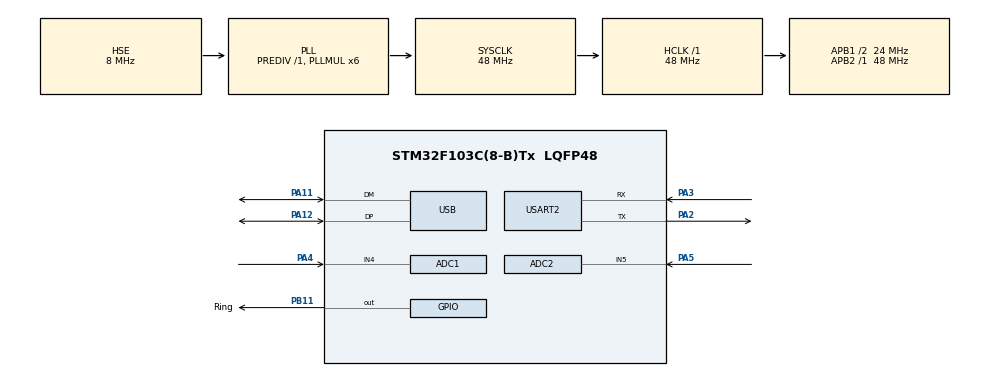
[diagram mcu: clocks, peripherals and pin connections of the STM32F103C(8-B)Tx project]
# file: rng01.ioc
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ADC1.Channel-0\#ChannelRegularConversion=ADC_CHANNEL_4
ADC1.NbrOfConversionFlag=1
ADC1.Rank-0\#ChannelRegularConversion=1
ADC1.SamplingTime-0\#ChannelRegularConversion=ADC_SAMPLETIME_1CYCLE_5
ADC1.master=1
ADC2.Channel-0\#ChannelRegularConversion=ADC_CHANNEL_5
ADC2.NbrOfConversionFlag=1
ADC2.Rank-0\#ChannelRegularConversion=1
ADC2.SamplingTime-0\#ChannelRegularConversion=ADC_SAMPLETIME_1CYCLE_5
FREERTOS.Tasks01=defaultTask,24,128,StartDefaultTask,Default,NULL,Dynamic,NULL,NULL
Mcu.Family=STM32F1
Mcu.Name=STM32F103C(8-B)Tx
Mcu.Package=LQFP48
NVIC.ADC1_2_IRQn=true\:5\:0\:false\:false\:true\:true\:true\:true\:true
NVIC.PriorityGroup=NVIC_PRIORITYGROUP_4
NVIC.RTC_Alarm_IRQn=true\:5\:0\:false\:false\:true\:true\:true\:true\:true
NVIC.RTC_IRQn=true\:5\:0\:false\:false\:true\:true\:true\:true\:true
NVIC.USBWakeUp_IRQn=true\:5\:0\:false\:false\:true\:true\:false\:true\:true
NVIC.USB_LP_CAN1_RX0_IRQn=true\:5\:0\:false\:false\:true\:true\:false\:true\:true
PA11.Mode=Device
PA11.Signal=USB_DM
PA12.Mode=Device
PA12.Signal=USB_DP
PA13.Mode=Serial_Wire
PA13.Signal=SYS_JTMS-SWDIO
PA14.Mode=Serial_Wire
PA14.Signal=SYS_JTCK-SWCLK
PA2.Mode=Asynchronous
PA2.Signal=USART2_TX
PA3.Mode=Asynchronous
PA3.Signal=USART2_RX
PA4.Signal=ADCx_IN4
PA5.Signal=ADCx_IN5
PB11.GPIO_Label=Ring
PB11.GPIO_Speed=GPIO_SPEED_FREQ_HIGH
PB11.PinState=GPIO_PIN_SET
PB11.Signal=GPIO_Output
PD0-OSC_IN.Mode=HSE-External-Oscillator
PD0-OSC_IN.Signal=RCC_OSC_IN
PD1-OSC_OUT.Mode=HSE-External-Oscillator
PD1-OSC_OUT.Signal=RCC_OSC_OUT
ProjectManager.HeapSize=0x200
ProjectManager.StackSize=0x400
ProjectManager.TargetToolchain=Makefile
RCC.ADCPresc=RCC_ADCPCLK2_DIV6
RCC.AHBFreq_Value=48000000
RCC.APB1CLKDivider=RCC_HCLK_DIV2
RCC.APB1Freq_Value=24000000
RCC.APB1TimFreq_Value=48000000
RCC.APB2Freq_Value=48000000
RCC.APB2TimFreq_Value=48000000
RCC.HCLKFreq_Value=48000000
RCC.PLLMUL=RCC_PLL_MUL6
RCC.SYSCLKFreq_VALUE=48000000
RCC.SYSCLKSource=RCC_SYSCLKSOURCE_PLLCLK
RCC.USBFreq_Value=48000000
SH.ADCx_IN4.0=ADC1_IN4,IN4
SH.ADCx_IN5.0=ADC2_IN5,IN5
TIM1.Period=0xffff-1
TIM1.Prescaler=48 -1
TIM1.RepetitionCounter=0
USART2.VirtualMode=VM_ASYNC
USB.low_power_enable=ENABLE
USB.lpm_enable=ENABLE
USB_DEVICE.CLASS_NAME_FS=CDC
USB_DEVICE.MANUFACTURER_STRING=EOS
USB_DEVICE.PRODUCT_STRING_CDC_FS=BluePill
USB_DEVICE.VirtualMode=Cdc
USB_DEVICE.VirtualModeFS=Cdc_FS
VP_FREERTOS_VS_CMSIS_V2.Mode=CMSIS_V2
VP_RTC_VS_RTC_Activate.Mode=RTC_Enabled
VP_TIM1_VS_ClockSourceINT.Mode=Internal
VP_USB_DEVICE_VS_USB_DEVICE_CDC_FS.Mode=CDC_FS
board=custom

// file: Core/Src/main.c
/* USER CODE BEGIN Header */
/**
  ******************************************************************************
  * @file           : main.c
  * @brief          : Main program body
  ******************************************************************************
  * @attention
  *
  * Copyright (c) 2024 STMicroelectronics.
  * All rights reserved.
  *
  * This software is licensed under terms that can be found in the LICENSE file
  * in the root directory of this software component.
  * If no LICENSE file comes with this software, it is provided AS-IS.
  *
  ******************************************************************************
  */
/* USER CODE END Header */
#include "main.h"
#include "cmsis_os.h"
#include "usb_device.h"
#include "usbd_cdc_if.h"
#include "ring.h"

ADC_HandleTypeDef hadc1;
ADC_HandleTypeDef hadc2;

RTC_HandleTypeDef hrtc;

TIM_HandleTypeDef htim1;

UART_HandleTypeDef huart2;

/* Definitions for defaultTask */
osThreadId_t defaultTaskHandle;
const osThreadAttr_t defaultTask_attributes = {
  .name = "defaultTask",
  .stack_size = 128 * 4,
  .priority = (osPriority_t) osPriorityNormal,
};

void SystemClock_Config(void);
static void MX_GPIO_Init(void);
static void MX_USART2_UART_Init(void);
static void MX_ADC1_Init(void);
static void MX_ADC2_Init(void);
static void MX_RTC_Init(void);
static void MX_TIM1_Init(void);
void StartDefaultTask(void *argument);

/* USER CODE BEGIN 0 */

int _write(int file, char *ptr, int len) {
    CDC_Transmit_FS((uint8_t*) ptr, len); return len;
}

/* USER CODE END 0 */

int main(void)
{

  /* MCU Configuration--------------------------------------------------------*/

  /* Reset of all peripherals, Initializes the Flash interface and the Systick. */
  HAL_Init();

  /* Configure the system clock */
  SystemClock_Config();

  /* Initialize all configured peripherals */
  MX_GPIO_Init();
  MX_USART2_UART_Init();
  MX_ADC1_Init();
  MX_ADC2_Init();
  MX_RTC_Init();
  MX_TIM1_Init();
  /* USER CODE BEGIN 2 */
  HAL_TIM_Base_Start(&htim1);
  /* USER CODE END 2 */

  /* Init scheduler */
  osKernelInitialize();

  /* Create the thread(s) */
  /* creation of defaultTask */
  defaultTaskHandle = osThreadNew(StartDefaultTask, NULL, &defaultTask_attributes);

  /* Start scheduler */
  osKernelStart();

  /* We should never get here as control is now taken by the scheduler */

  /* Infinite loop */
  while (1)
  {

  }
}

void SystemClock_Config(void)
{
  RCC_OscInitTypeDef RCC_OscInitStruct = {0};
  RCC_ClkInitTypeDef RCC_ClkInitStruct = {0};
  RCC_PeriphCLKInitTypeDef PeriphClkInit = {0};

  /** Initializes the RCC Oscillators according to the specified parameters
  * in the RCC_OscInitTypeDef structure.
  */
  RCC_OscInitStruct.OscillatorType = RCC_OSCILLATORTYPE_LSI|RCC_OSCILLATORTYPE_HSE;
  RCC_OscInitStruct.HSEState = RCC_HSE_ON;
  RCC_OscInitStruct.HSEPredivValue = RCC_HSE_PREDIV_DIV1;
  RCC_OscInitStruct.HSIState = RCC_HSI_ON;
  RCC_OscInitStruct.LSIState = RCC_LSI_ON;
  RCC_OscInitStruct.PLL.PLLState = RCC_PLL_ON;
  RCC_OscInitStruct.PLL.PLLSource = RCC_PLLSOURCE_HSE;
  RCC_OscInitStruct.PLL.PLLMUL = RCC_PLL_MUL6;
  if (HAL_RCC_OscConfig(&RCC_OscInitStruct) != HAL_OK)
  {
    Error_Handler();
  }

  /** Initializes the CPU, AHB and APB buses clocks
  */
  RCC_ClkInitStruct.ClockType = RCC_CLOCKTYPE_HCLK|RCC_CLOCKTYPE_SYSCLK
                              |RCC_CLOCKTYPE_PCLK1|RCC_CLOCKTYPE_PCLK2;
  RCC_ClkInitStruct.SYSCLKSource = RCC_SYSCLKSOURCE_PLLCLK;
  RCC_ClkInitStruct.AHBCLKDivider = RCC_SYSCLK_DIV1;
  RCC_ClkInitStruct.APB1CLKDivider = RCC_HCLK_DIV2;
  RCC_ClkInitStruct.APB2CLKDivider = RCC_HCLK_DIV1;

  if (HAL_RCC_ClockConfig(&RCC_ClkInitStruct, FLASH_LATENCY_1) != HAL_OK)
  {
    Error_Handler();
  }
  PeriphClkInit.PeriphClockSelection = RCC_PERIPHCLK_RTC|RCC_PERIPHCLK_ADC
                              |RCC_PERIPHCLK_USB;
  PeriphClkInit.RTCClockSelection = RCC_RTCCLKSOURCE_LSI;
  PeriphClkInit.AdcClockSelection = RCC_ADCPCLK2_DIV6;
  PeriphClkInit.UsbClockSelection = RCC_USBCLKSOURCE_PLL;
  if (HAL_RCCEx_PeriphCLKConfig(&PeriphClkInit) != HAL_OK)
  {
    Error_Handler();
  }
}

static void MX_ADC1_Init(void)
{

  ADC_ChannelConfTypeDef sConfig = {0};

  /** Common config
  */
  hadc1.Instance = ADC1;
  hadc1.Init.ScanConvMode = ADC_SCAN_DISABLE;
  hadc1.Init.ContinuousConvMode = DISABLE;
  hadc1.Init.DiscontinuousConvMode = DISABLE;
  hadc1.Init.ExternalTrigConv = ADC_SOFTWARE_START;
  hadc1.Init.DataAlign = ADC_DATAALIGN_RIGHT;
  hadc1.Init.NbrOfConversion = 1;
  if (HAL_ADC_Init(&hadc1) != HAL_OK)
  {
    Error_Handler();
  }

  /** Configure Regular Channel
  */
  sConfig.Channel = ADC_CHANNEL_4;
  sConfig.Rank = ADC_REGULAR_RANK_1;
  sConfig.SamplingTime = ADC_SAMPLETIME_1CYCLE_5;
  if (HAL_ADC_ConfigChannel(&hadc1, &sConfig) != HAL_OK)
  {
    Error_Handler();
  }

}

static void MX_ADC2_Init(void)
{

  ADC_ChannelConfTypeDef sConfig = {0};

  /** Common config
  */
  hadc2.Instance = ADC2;
  hadc2.Init.ScanConvMode = ADC_SCAN_DISABLE;
  hadc2.Init.ContinuousConvMode = DISABLE;
  hadc2.Init.DiscontinuousConvMode = DISABLE;
  hadc2.Init.ExternalTrigConv = ADC_SOFTWARE_START;
  hadc2.Init.DataAlign = ADC_DATAALIGN_RIGHT;
  hadc2.Init.NbrOfConversion = 1;
  if (HAL_ADC_Init(&hadc2) != HAL_OK)
  {
    Error_Handler();
  }

  /** Configure Regular Channel
  */
  sConfig.Channel = ADC_CHANNEL_5;
  sConfig.Rank = ADC_REGULAR_RANK_1;
  sConfig.SamplingTime = ADC_SAMPLETIME_1CYCLE_5;
  if (HAL_ADC_ConfigChannel(&hadc2, &sConfig) != HAL_OK)
  {
    Error_Handler();
  }

}

static void MX_RTC_Init(void)
{

  /** Initialize RTC Only
  */
  hrtc.Instance = RTC;
  hrtc.Init.AsynchPrediv = RTC_AUTO_1_SECOND;
  hrtc.Init.OutPut = RTC_OUTPUTSOURCE_ALARM;
  if (HAL_RTC_Init(&hrtc) != HAL_OK)
  {
    Error_Handler();
  }

}

static void MX_TIM1_Init(void)
{

  TIM_ClockConfigTypeDef sClockSourceConfig = {0};
  TIM_MasterConfigTypeDef sMasterConfig = {0};

  htim1.Instance = TIM1;
  htim1.Init.Prescaler = 48 -1;
  htim1.Init.CounterMode = TIM_COUNTERMODE_UP;
  htim1.Init.Period = 0xffff-1;
  htim1.Init.ClockDivision = TIM_CLOCKDIVISION_DIV1;
  htim1.Init.RepetitionCounter = 0;
  htim1.Init.AutoReloadPreload = TIM_AUTORELOAD_PRELOAD_DISABLE;
  if (HAL_TIM_Base_Init(&htim1) != HAL_OK)
  {
    Error_Handler();
  }
  sClockSourceConfig.ClockSource = TIM_CLOCKSOURCE_INTERNAL;
  if (HAL_TIM_ConfigClockSource(&htim1, &sClockSourceConfig) != HAL_OK)
  {
    Error_Handler();
  }
  sMasterConfig.MasterOutputTrigger = TIM_TRGO_RESET;
  sMasterConfig.MasterSlaveMode = TIM_MASTERSLAVEMODE_DISABLE;
  if (HAL_TIMEx_MasterConfigSynchronization(&htim1, &sMasterConfig) != HAL_OK)
  {
    Error_Handler();
  }

}

static void MX_USART2_UART_Init(void)
{

  huart2.Instance = USART2;
  huart2.Init.BaudRate = 115200;
  huart2.Init.WordLength = UART_WORDLENGTH_8B;
  huart2.Init.StopBits = UART_STOPBITS_1;
  huart2.Init.Parity = UART_PARITY_NONE;
  huart2.Init.Mode = UART_MODE_TX_RX;
  huart2.Init.HwFlowCtl = UART_HWCONTROL_NONE;
  huart2.Init.OverSampling = UART_OVERSAMPLING_16;
  if (HAL_UART_Init(&huart2) != HAL_OK)
  {
    Error_Handler();
  }

}

static void MX_GPIO_Init(void)
{
  GPIO_InitTypeDef GPIO_InitStruct = {0};

  /* GPIO Ports Clock Enable */
  __HAL_RCC_GPIOD_CLK_ENABLE();
  __HAL_RCC_GPIOA_CLK_ENABLE();
  __HAL_RCC_GPIOB_CLK_ENABLE();

  /*Configure GPIO pin Output Level */
  HAL_GPIO_WritePin(Ring_GPIO_Port, Ring_Pin, GPIO_PIN_RESET);

  /*Configure GPIO pin : Ring_Pin */
  GPIO_InitStruct.Pin = Ring_Pin;
  GPIO_InitStruct.Mode = GPIO_MODE_OUTPUT_PP;
  GPIO_InitStruct.Pull = GPIO_NOPULL;
  GPIO_InitStruct.Speed = GPIO_SPEED_FREQ_HIGH;
  HAL_GPIO_Init(Ring_GPIO_Port, &GPIO_InitStruct);

}

static bool random_move_flag = false;

void set_randome_move(bool f)
{
    random_move_flag = f;
}

bool get_randome_move(void)
{
    return random_move_flag;
}

void StartDefaultTask(void *argument)
{
  /* init code for USB_DEVICE */
  MX_USB_DEVICE_Init();
  /* USER CODE BEGIN 5 */

  restore_led();
  ring_flash();

  /* Infinite loop */
  for(;;)
  {
     osDelay(1000);
     if(random_move_flag) {
        ring_all_color_set_random_move();
     }
  }
  /* USER CODE END 5 */
}

void Error_Handler(void)
{
  __disable_irq();
  while (1)
  {
  }
}

uint32_t adc_random(void)
{
    uint32_t val;
    HAL_ADC_Start(&hadc1);
    HAL_ADC_PollForConversion(&hadc1, HAL_MAX_DELAY);

    val = HAL_ADC_GetValue(&hadc1);

    HAL_ADC_Stop(&hadc1);

    return val;
}
